# NUC100CN_v1 register map
File version: 1.0
Registers are 32-bit, read-write, reset 0x0 unless marked. A register's access mark holds for its fields unless they carry their own. Offsets are from the block's base; [hi:lo] are bit positions; 'fields as' and 'values as' point back to an identical list.

## WDT — WDT Register Map
Base 0x40004000
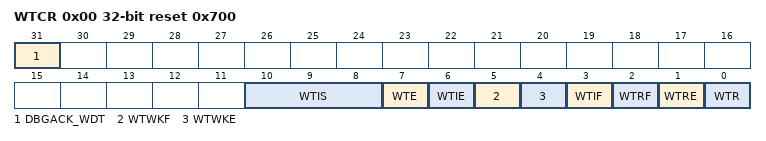
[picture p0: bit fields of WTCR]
0x00 WTCR reset 0x700 — Watchdog Timer Control Register
  [31] DBGACK_WDT — ICE Debug Mode Acknowledge Disable (Write-protection Bit). Watchdog Timer counter will keep going no matter ICE debug mode acknowledged or not.
    0=ICE debug mode acknowledgement effects Watchdog Timer counting; 1=ICE debug mode acknowledgement Disabled
  [10:8] WTIS — Watchdog Timer Interval Selection (Write-protection Bits)
  [7] WTE — Watchdog Timer Enable (Write-protection Bit)
    0=Watchdog timer Disabled (this action will reset the internal counter); 1=Watchdog timer Enabled
  [6] WTIE — Watchdog Timer Interrupt Enable (Write-protection Bit)
    0=Watchdog timer interrupt Disabled; 1=Watchdog timer interrupt Enabled
  [5] WTWKF — Watchdog Timer Wake-up Flag. If Watchdog timer causes chip wakes up from Power-down mode, this bit will be set to high. It must be cleared by software with a write 1 to this bit.
    0=Watchdog timer does not cause chip wake-up; 1=Chip wake-up from idle or Power-down mode by Watchdog timeout
  [4] WTWKE — Watchdog Timer Wake-up Function Enable bit (Write-protection Bit). Note: Chip can wake-up by WDT only if WDT clock source select RC10K
    0=Watchdog timer Wake-up chip function Disabled; 1=Wake-up function Enabled so that Watchdog timer timeout can wake up chip from Power-down mode
  [3] WTIF — Watchdog Timer Interrupt Flag. If the Watchdog timer interrupt is enabled, then the hardware will set this bit to indicate that the Watchdog timer interrupt has occurred. Note: This bit is cleared by writing 1 to this bit.
    0=Watchdog timer interrupt did not occur; 1=Watchdog timer interrupt occurred
  [2] WTRF — Watchdog Timer Reset Flag. When the Watchdog timer initiates a reset, the hardware will set this bit. This flag can be read by software to determine the source of reset. Software is responsible to clear it manually by writing 1 to it. If WTRE is disabled, then the Watchdog timer has no effect on this bit. Note: This bit is cleared by writing 1 to this bit.
    0=Watchdog timer reset did not occur; 1=Watchdog timer reset occurred
  [1] WTRE — Watchdog Timer Reset Enable (Write-protection Bit). Setting this bit will enable the Watchdog timer reset function.
    0=Watchdog timer reset function Disabled; 1=Watchdog timer reset function Enabled
  [0] WTR — Clear Watchdog Timer (Write-protection Bit). Setting this bit will clear the Watchdog timer. Note: This bit will be auto cleared by hardware
    0=No effect; 1=Reset the contents of the Watchdog timer

## CMP — CMP Register Map
Base 0x400D0000
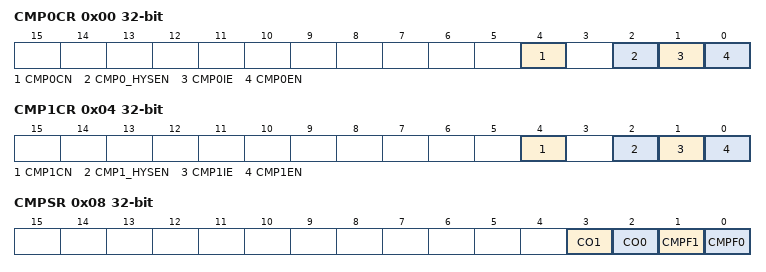
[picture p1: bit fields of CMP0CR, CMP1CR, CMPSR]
0x00 CMP0CR — Comparator0 Control Register
  [4] CMP0CN — Comparator0 Negative Input Selection
    0=The source of the negative comparator input is from CPN0 pin; 1=The internal band-gap reference voltage is selected as the source of negative comparator input
  [2] CMP0_HYSEN — Comparator0 Hysteresis Enable
    0=Hysteresis function Disabled (Default); 1=Hysteresis function Enabled. The typical range is 20 mV
  [1] CMP0IE — Comparator0 Interrupt Enable
    0=Interrupt function Disabled; 1=Interrupt function Enabled
  [0] CMP0EN — Comparator0 Enable. Comparator output needs wait 2 us stable time after CMP0EN is set.
    0=Disabled; 1=Enabled
0x04 CMP1CR — Comparator1 Control Register
  [4] CMP1CN — Comparator1 Negative Input Selection
    0=The source of the negative comparator input is from CPN1 pin; 1=The internal band-gap reference voltage is selected as the source of negative comparator input
  [2] CMP1_HYSEN — Comparator1 Hysteresis Enable
    values as CMP0CR.CMP0_HYSEN
  [1] CMP1IE — Comparator1 Interrupt Enable
    0=Interrupt function Disabled; 1=Interrupt function Enabled
  [0] CMP1EN — Comparator1 Enable. Comparator output needs to wait 2 us stable time after CMP1EN is set.
    0=Disabled; 1=Enabled
0x08 CMPSR — Comparator Status Register
  [3] CO1 — Comparator1 Output
  [2] CO0 — Comparator0 Output
  [1] CMPF1 — Comparator1 Flag. This bit is set by hardware whenever the comparator1 output changes state. This will cause an interrupt if CMP1IE set. Write 1 to clear this bit to 0.
  [0] CMPF0 — Comparator0 Flag. This bit is set by hardware whenever the comparator0 output changes state. This will cause an interrupt if CMP0IE set. Write 1 to clear this bit to 0.
